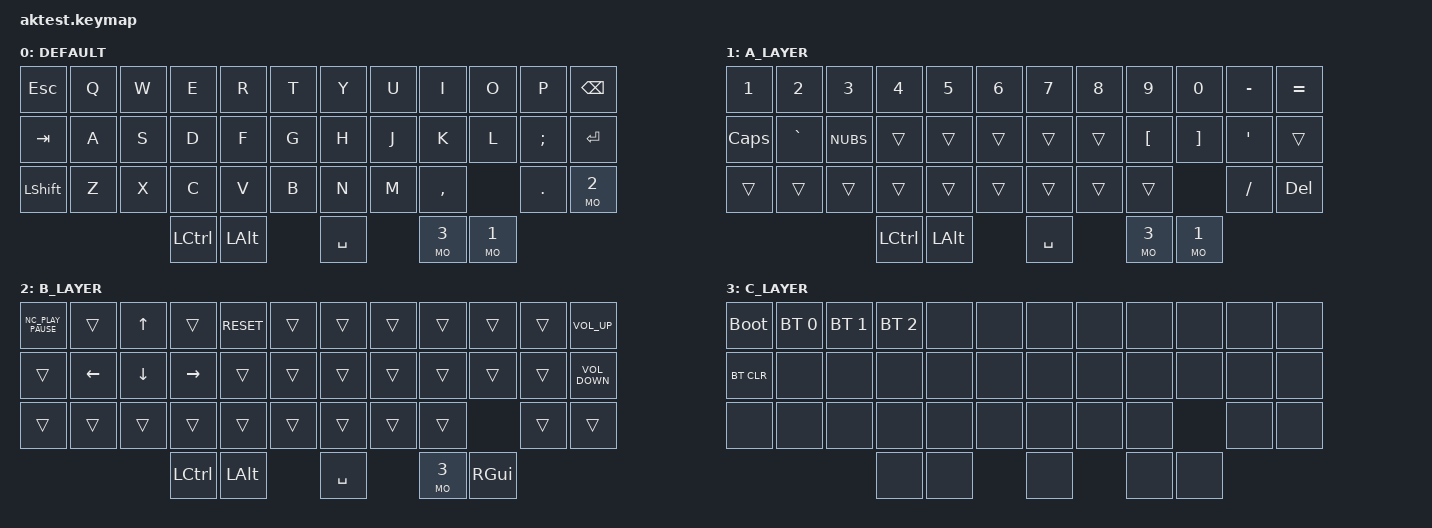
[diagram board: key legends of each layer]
#include <behaviors.dtsi>
#include <dt-bindings/zmk/keys.h>
#include <dt-bindings/zmk/bt.h>

#define DEFAULT 0
#define A_LAYER   1
#define B_LAYER   2
#define C_LAYER   3
    
/ keymap {
        compatible = "zmk,keymap";

        DEFAULT {
            bindings = 
                &kp ESC    &kp Q    &kp W    &kp E    &kp R    &kp T    &kp Y    &kp U    &kp I    &kp O    &kp P    &kp BACKSPACE
                &kp TAB    &kp A    &kp S    &kp D    &kp F    &kp G    &kp H    &kp J    &kp K    &kp L    &kp SEMICOLON    &kp ENTER
                &kp LSHIFT    &kp Z    &kp X    &kp C    &kp V    &kp B    &kp N    &kp M    &kp COMMA    &kp PERIOD    &MO 2   
                                            &kp LCTRL    &kp LALT        &kp SPACE          &MO 3    &MO 1      
            >;
        };

        A_LAYER {
            bindings = <
                &kp N1    &kp N2    &kp N3    &kp N4    &kp N5    &kp N6    &kp N7    &kp N8    &kp N9    &kp N0    &kp MINUS    &kp EQUAL
                &kp CAPS    &kp GRAVE    &kp NUBS    &trans    &trans    &trans    &trans    &trans    &kp LEFT_BRACKET    &kp RIGHT_BRACKET    &kp SINGLE_QUOTE    &trans
                &trans   &trans    &trans    &trans    &trans    &trans    &trans    &trans    &trans    &kp SLASH    &kp DELETE   
                                            &kp LCTRL    &kp LALT        &kp SPACE          &MO 3    &MO 1      
            >;
        }; 

        B_LAYER {
            bindings = <
                &kp NC_PLAY_PAUSE    &trans    &kp UP_ARROW    &trans    &kp RESET    &trans    &trans    &trans    &trans    &trans   &trans   &kp C_VOLUME_UP
                &trans    &kp LEFT_ARROW    &kp DOWN_ARROW   &kp RIGHT_ARROW    &trans    &trans    &trans    &trans    &trans    &trans    &trans    &kp C_VOLUME_DOWN
                &trans   &trans    &trans    &trans    &trans    &trans    &trans    &trans    &trans    &trans    &trans   
                                            &kp LCTRL    &kp LALT        &kp SPACE          &MO 3    &kp RIGHT_GUI  
            >;
        };

        C_LAYER {
            bindings = <
                &bootloader   &bt BT_SEL 0    &bt BT_SEL 1    &bt BT_SEL 2    &none    &none    &none    &none    &none    &none    &none    &none
                &bt BT_CLR    &none   &none    &none    &none    &none    &none    &none    &none    &none    &none    &none
                &none   &none    &none    &none    &none    &none    &none    &none    &none    &none    &none   
                                            &none    &none        &none          &none    &none  
            >;
        };

};
